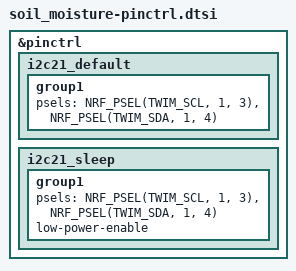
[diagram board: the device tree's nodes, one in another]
&pinctrl {
	/omit-if-no-ref/ i2c21_default: i2c21_default {
		group1 {
			psels = <NRF_PSEL(TWIM_SCL, 1, 3)>,
				<NRF_PSEL(TWIM_SDA, 1, 4)>;
		};
	};

	/omit-if-no-ref/ i2c21_sleep: i2c21_sleep {
		group1 {
			psels = <NRF_PSEL(TWIM_SCL, 1, 3)>,
				<NRF_PSEL(TWIM_SDA, 1, 4)>;
			low-power-enable;
		};
	};
};
